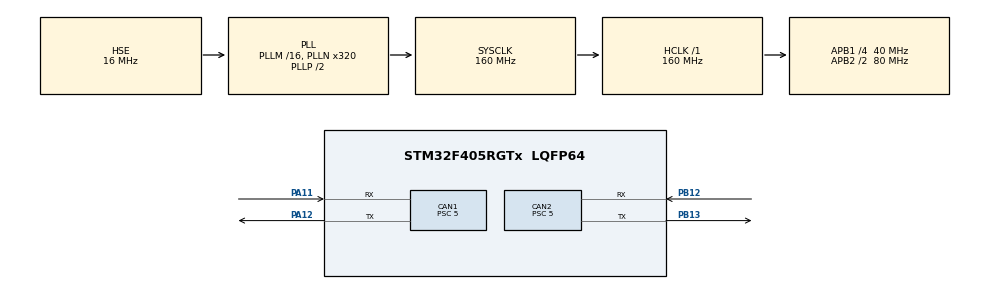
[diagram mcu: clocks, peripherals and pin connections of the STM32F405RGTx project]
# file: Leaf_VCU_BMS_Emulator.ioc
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CAN1.BS1=CAN_BS1_11TQ
CAN1.BS2=CAN_BS2_4TQ
CAN1.CalculateBaudRate=500000
CAN1.CalculateTimeBit=2000
CAN1.CalculateTimeQuantum=125.0
CAN1.NART=ENABLE
CAN1.Prescaler=5
CAN1.SJW=CAN_SJW_2TQ
CAN1.TXFP=ENABLE
CAN2.BS1=CAN_BS1_11TQ
CAN2.BS2=CAN_BS2_4TQ
CAN2.CalculateBaudRate=500000
CAN2.CalculateTimeBit=2000
CAN2.CalculateTimeQuantum=125.0
CAN2.NART=ENABLE
CAN2.Prescaler=5
CAN2.TXFP=ENABLE
Mcu.Family=STM32F4
Mcu.Name=STM32F405RGTx
Mcu.Package=LQFP64
NVIC.CAN1_RX0_IRQn=true\:0\:0\:false\:false\:true\:true\:true\:true
NVIC.CAN1_RX1_IRQn=true\:0\:0\:false\:false\:true\:true\:true\:true
NVIC.CAN1_SCE_IRQn=true\:0\:0\:false\:false\:true\:true\:true\:true
NVIC.CAN1_TX_IRQn=true\:0\:0\:false\:false\:true\:true\:true\:true
NVIC.CAN2_RX0_IRQn=true\:0\:0\:false\:false\:true\:true\:true\:true
NVIC.CAN2_RX1_IRQn=true\:0\:0\:false\:false\:true\:true\:true\:true
NVIC.CAN2_SCE_IRQn=true\:0\:0\:false\:false\:true\:true\:true\:true
NVIC.CAN2_TX_IRQn=true\:0\:0\:false\:false\:true\:true\:true\:true
NVIC.PriorityGroup=NVIC_PRIORITYGROUP_4
NVIC.TIM2_IRQn=true\:0\:0\:false\:false\:true\:true\:true\:true
PA11.Mode=CAN_Activate
PA11.Signal=CAN1_RX
PA12.Mode=CAN_Activate
PA12.Signal=CAN1_TX
PA13.Mode=Serial_Wire
PA13.Signal=SYS_JTMS-SWDIO
PA14.Mode=Serial_Wire
PA14.Signal=SYS_JTCK-SWCLK
PB12.Mode=CAN_Activate
PB12.Signal=CAN2_RX
PB13.Mode=CAN_Activate
PB13.Signal=CAN2_TX
PH0-OSC_IN.Mode=HSE-External-Oscillator
PH0-OSC_IN.Signal=RCC_OSC_IN
PH1-OSC_OUT.Mode=HSE-External-Oscillator
PH1-OSC_OUT.Signal=RCC_OSC_OUT
ProjectManager.HeapSize=0x400
ProjectManager.StackSize=0x800
ProjectManager.TargetToolchain=STM32CubeIDE
RCC.48MHZClocksFreq_Value=80000000
RCC.AHBFreq_Value=160000000
RCC.APB1CLKDivider=RCC_HCLK_DIV4
RCC.APB1Freq_Value=40000000
RCC.APB1TimFreq_Value=80000000
RCC.APB2CLKDivider=RCC_HCLK_DIV2
RCC.APB2Freq_Value=80000000
RCC.APB2TimFreq_Value=160000000
RCC.CortexFreq_Value=160000000
RCC.HCLKFreq_Value=160000000
RCC.HSE_VALUE=16000000
RCC.HSI_VALUE=16000000
RCC.LSE_VALUE=32768
RCC.PLLN=320
RCC.PLLSourceVirtual=RCC_PLLSOURCE_HSE
RCC.SYSCLKFreq_VALUE=160000000
RCC.SYSCLKSource=RCC_SYSCLKSOURCE_PLLCLK
RCC.VCOOutputFreq_Value=320000000
TIM2.AutoReloadPreload=TIM_AUTORELOAD_PRELOAD_ENABLE
TIM2.Period=1000
TIM2.Prescaler=80-1
VP_TIM2_VS_ClockSourceINT.Mode=Internal
board=custom

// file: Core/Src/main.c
/* USER CODE BEGIN Header */
/**
  ******************************************************************************
  * @file           : main.c
  * @brief          : Main program body
  ******************************************************************************
  * @attention
  *
  * Copyright (c) 2023 STMicroelectronics.
  * All rights reserved.
  *
  * This software is licensed under terms that can be found in the LICENSE file
  * in the root directory of this software component.
  * If no LICENSE file comes with this software, it is provided AS-IS.
  *
  ******************************************************************************
  */
/* USER CODE END Header */
#include "main.h"
#include "can.h"
#include "tim.h"
#include "gpio.h"

/* USER CODE BEGIN Includes */
#include "bms_if.h"
#include "vcu_if.h"
/* USER CODE END Includes */

void SystemClock_Config(void);

int main(void)
{

  /* MCU Configuration--------------------------------------------------------*/

  /* Reset of all peripherals, Initializes the Flash interface and the Systick. */
  HAL_Init();

  /* Configure the system clock */
  SystemClock_Config();

  /* Initialize all configured peripherals */
  MX_GPIO_Init();
  MX_CAN1_Init();
  MX_CAN2_Init();
  MX_TIM2_Init();
  /* USER CODE BEGIN 2 */
  InitCAN_if();
    HAL_TIM_Base_Start_IT(&htim2);
  /* USER CODE END 2 */

  /* Infinite loop */
  while (1)
  {

  }
}

void SystemClock_Config(void)
{
  RCC_OscInitTypeDef RCC_OscInitStruct = {0};
  RCC_ClkInitTypeDef RCC_ClkInitStruct = {0};

  /** Configure the main internal regulator output voltage
  */
  __HAL_RCC_PWR_CLK_ENABLE();
  __HAL_PWR_VOLTAGESCALING_CONFIG(PWR_REGULATOR_VOLTAGE_SCALE1);

  /** Initializes the RCC Oscillators according to the specified parameters
  * in the RCC_OscInitTypeDef structure.
  */
  RCC_OscInitStruct.OscillatorType = RCC_OSCILLATORTYPE_HSE;
  RCC_OscInitStruct.HSEState = RCC_HSE_ON;
  RCC_OscInitStruct.PLL.PLLState = RCC_PLL_ON;
  RCC_OscInitStruct.PLL.PLLSource = RCC_PLLSOURCE_HSE;
  RCC_OscInitStruct.PLL.PLLM = 16;
  RCC_OscInitStruct.PLL.PLLN = 320;
  RCC_OscInitStruct.PLL.PLLP = RCC_PLLP_DIV2;
  RCC_OscInitStruct.PLL.PLLQ = 4;
  if (HAL_RCC_OscConfig(&RCC_OscInitStruct) != HAL_OK)
  {
    Error_Handler();
  }

  /** Initializes the CPU, AHB and APB buses clocks
  */
  RCC_ClkInitStruct.ClockType = RCC_CLOCKTYPE_HCLK|RCC_CLOCKTYPE_SYSCLK
                              |RCC_CLOCKTYPE_PCLK1|RCC_CLOCKTYPE_PCLK2;
  RCC_ClkInitStruct.SYSCLKSource = RCC_SYSCLKSOURCE_PLLCLK;
  RCC_ClkInitStruct.AHBCLKDivider = RCC_SYSCLK_DIV1;
  RCC_ClkInitStruct.APB1CLKDivider = RCC_HCLK_DIV4;
  RCC_ClkInitStruct.APB2CLKDivider = RCC_HCLK_DIV2;

  if (HAL_RCC_ClockConfig(&RCC_ClkInitStruct, FLASH_LATENCY_5) != HAL_OK)
  {
    Error_Handler();
  }
}

/* USER CODE BEGIN 4 */

void HAL_TIM_PeriodElapsedCallback(TIM_HandleTypeDef *htim){
    SendVCMDataProcess();
    SendBMSDataProcess();
}

/* USER CODE END 4 */

void Error_Handler(void)
{
  __disable_irq();
  while (1)
  {
  }
}
